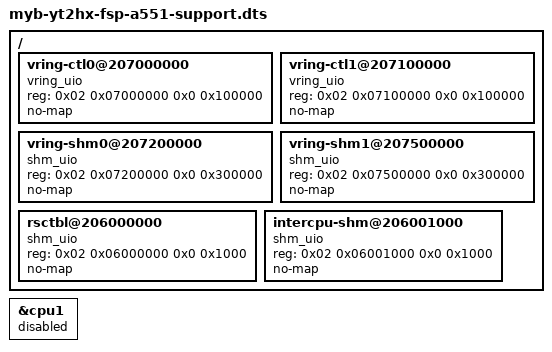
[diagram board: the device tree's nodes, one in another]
// SPDX-License-Identifier: (GPL-2.0-only OR BSD-2-Clause)
/*
 * Device Tree Source for the RZ/T2H Development EVK board
 *
 * Copyright (C) 2023 Renesas Electronics Corp.
 */

//#include "r9a09g077m44-dev.dts"
#include "myb-yt2hx-base.dts"

&cpu1 {
	status = "disabled";
	/delete-property/ enable-method;
};

/delete-node/ &{/vring-ctl0@261000000};
/delete-node/ &{/vring-ctl1@261100000};
/delete-node/ &{/vring-shm0@261200000};
/delete-node/ &{/vring-shm1@261500000};
/delete-node/ &{/rsctbl@260000000};
/delete-node/ &{/intercpu-shm@260001000};

/ {
	vring-ctl0@207000000 {
		compatible = "vring_uio";
		reg = <0x02 0x07000000 0x0 0x100000>;
		no-map;
	};

	vring-ctl1@207100000 {
		compatible = "vring_uio";
		reg = <0x02 0x07100000 0x0 0x100000>;
		no-map;
	};

	vring-shm0@207200000 {
		compatible = "shm_uio";
		reg = <0x02 0x07200000 0x0 0x300000>;
		no-map;
	};

	vring-shm1@207500000 {
		compatible = "shm_uio";
		reg = <0x02 0x07500000 0x0 0x300000>;
		no-map;
	};

	rsctbl@206000000 {
		compatible = "shm_uio";
		reg = <0x02 0x06000000 0x0 0x1000>;
		no-map;
	};

	intercpu-shm@206001000 {
		compatible = "shm_uio";
		reg = <0x02 0x06001000 0x0 0x1000>;
		no-map;
	};
};
